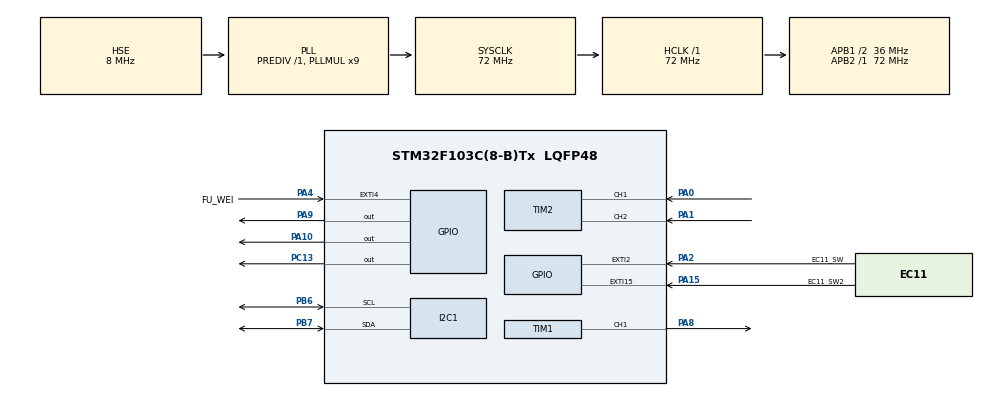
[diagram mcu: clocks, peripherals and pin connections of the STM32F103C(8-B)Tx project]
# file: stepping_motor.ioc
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I2C1.I2C_Mode=I2C_Standard
Mcu.Family=STM32F1
Mcu.Name=STM32F103C(8-B)Tx
Mcu.Package=LQFP48
NVIC.EXTI15_10_IRQn=true\:0\:0\:false\:false\:true\:true\:true\:true
NVIC.EXTI2_IRQn=true\:0\:0\:false\:false\:true\:true\:true\:true
NVIC.EXTI4_IRQn=true\:0\:0\:false\:false\:true\:true\:true\:true
NVIC.PriorityGroup=NVIC_PRIORITYGROUP_4
NVIC.TIM1_BRK_IRQn=true\:0\:0\:false\:false\:true\:true\:true\:true
NVIC.TIM1_CC_IRQn=true\:0\:0\:false\:false\:true\:true\:true\:true
NVIC.TIM1_TRG_COM_IRQn=true\:0\:0\:false\:false\:true\:true\:true\:true
NVIC.TIM1_UP_IRQn=true\:0\:0\:false\:false\:true\:true\:true\:true
NVIC.TIM3_IRQn=true\:0\:0\:false\:false\:true\:true\:true\:true
PA0-WKUP.GPIO_PuPd=GPIO_PULLUP
PA0-WKUP.Signal=S_TIM2_CH1_ETR
PA1.GPIO_PuPd=GPIO_PULLUP
PA1.Signal=S_TIM2_CH2
PA10.Signal=GPIO_Output
PA13.Mode=Serial_Wire
PA13.Signal=SYS_JTMS-SWDIO
PA14.Mode=Serial_Wire
PA14.Signal=SYS_JTCK-SWCLK
PA15.GPIO_Label=EC11_SW2
PA15.GPIO_ModeDefaultEXTI=GPIO_MODE_IT_FALLING
PA15.GPIO_PuPd=GPIO_PULLUP
PA15.Signal=GPXTI15
PA2.GPIO_Label=EC11_SW
PA2.GPIO_ModeDefaultEXTI=GPIO_MODE_IT_FALLING
PA2.GPIO_PuPd=GPIO_PULLUP
PA2.Signal=GPXTI2
PA4.GPIO_Label=FU_WEI
PA4.GPIO_ModeDefaultEXTI=GPIO_MODE_IT_FALLING
PA4.GPIO_PuPd=GPIO_PULLUP
PA4.Signal=GPXTI4
PA8.Signal=S_TIM1_CH1
PA9.Signal=GPIO_Output
PB6.Mode=I2C
PB6.Signal=I2C1_SCL
PB7.Mode=I2C
PB7.Signal=I2C1_SDA
PC13-TAMPER-RTC.PinState=GPIO_PIN_SET
PC13-TAMPER-RTC.Signal=GPIO_Output
PD0-OSC_IN.Mode=HSE-External-Oscillator
PD0-OSC_IN.Signal=RCC_OSC_IN
PD1-OSC_OUT.Mode=HSE-External-Oscillator
PD1-OSC_OUT.Signal=RCC_OSC_OUT
ProjectManager.HeapSize=0x200
ProjectManager.StackSize=0x400
ProjectManager.TargetToolchain=MDK-ARM V5.32
RCC.AHBFreq_Value=72000000
RCC.APB1CLKDivider=RCC_HCLK_DIV2
RCC.APB1Freq_Value=36000000
RCC.APB1TimFreq_Value=72000000
RCC.APB2Freq_Value=72000000
RCC.APB2TimFreq_Value=72000000
RCC.HCLKFreq_Value=72000000
RCC.PLLMUL=RCC_PLL_MUL9
RCC.PLLSourceVirtual=RCC_PLLSOURCE_HSE
RCC.SYSCLKFreq_VALUE=72000000
RCC.SYSCLKSource=RCC_SYSCLKSOURCE_PLLCLK
RCC.USBFreq_Value=72000000
SH.S_TIM1_CH1.0=TIM1_CH1,PWM Generation1 CH1
SH.S_TIM2_CH1_ETR.0=TIM2_CH1,Encoder_Interface
SH.S_TIM2_CH2.0=TIM2_CH2,Encoder_Interface
TIM1.Channel-PWM\ Generation1\ CH1=TIM_CHANNEL_1
TIM1.Period=999
TIM1.Prescaler=71
TIM1.Pulse-PWM\ Generation1\ CH1=500
TIM2.EncoderMode=TIM_ENCODERMODE_TI12
TIM2.IC1Filter=12
TIM2.IC2Filter=12
TIM3.Period=1000-1
TIM3.Prescaler=72-1
VP_TIM1_VS_ClockSourceINT.Mode=Internal
VP_TIM3_VS_ClockSourceINT.Mode=Internal
board=custom

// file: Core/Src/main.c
/* USER CODE BEGIN Header */
/**
  ******************************************************************************
  * @file           : main.c
  * @brief          : Main program body
  ******************************************************************************
  * @attention
  *
  * Copyright (c) 2026 STMicroelectronics.
  * All rights reserved.
  *
  * This software is licensed under terms that can be found in the LICENSE file
  * in the root directory of this software component.
  * If no LICENSE file comes with this software, it is provided AS-IS.
  *
  ******************************************************************************
  */
/* USER CODE END Header */
#include "main.h"
#include "i2c.h"
#include "tim.h"
#include "gpio.h"

/* USER CODE BEGIN Includes */
#include "headfile.h"
/* USER CODE END Includes */

void SystemClock_Config(void);

int main(void)
{

  /* MCU Configuration--------------------------------------------------------*/

  /* Reset of all peripherals, Initializes the Flash interface and the Systick. */
  HAL_Init();

  /* Configure the system clock */
  SystemClock_Config();

  /* USER CODE BEGIN SysInit */
HAL_Delay(1500);
  /* USER CODE END SysInit */

  /* Initialize all configured peripherals */
  MX_GPIO_Init();
  MX_I2C1_Init();
  MX_TIM1_Init();
  MX_TIM2_Init();
  MX_TIM3_Init();
  /* USER CODE BEGIN 2 */
//	HAL_Delay(500);
	OLED_Init();
  //OLED_Fill(0xFF);
  //HAL_Delay(2000);
  OLED_Fill(0x00);

	//OLED_ShowString(30, 2, "HELLO");

	HAL_TIM_Encoder_Start(&htim2, TIM_CHANNEL_ALL);
	//__HAL_TIM_SET_COUNTER(&htim2, 0);
	Load_Parameters();

	__HAL_TIM_SET_COUNTER(&htim2,0);

  HAL_GPIO_WritePin(GPIOA, GPIO_PIN_9, GPIO_PIN_SET);

  //HAL_TIM_PWM_Start(&htim1, TIM_CHANNEL_1);

  //__HAL_TIM_SET_AUTORELOAD(&htim1, 1250-1);//ARR

  //__HAL_TIM_SET_COMPARE(&htim1, TIM_CHANNEL_1, 625);//zhankongbi

	//dianji_kongzhi(up,90,800);
//	HAL_Delay(5000);
//	HAL_TIM_PWM_Stop(&htim1, TIM_CHANNEL_1);
  /* USER CODE END 2 */

  /* Infinite loop */
  /* USER CODE BEGIN WHILE */
  while (1)
  {
		main_pro();
//		HAL_GPIO_WritePin(GPIOC,GPIO_PIN_13,GPIO_PIN_RESET);
//		HAL_Delay(1000);
//		HAL_GPIO_WritePin(GPIOC,GPIO_PIN_13,GPIO_PIN_SET);
//		HAL_Delay(1000);
    /* USER CODE END WHILE */

  }
}

void SystemClock_Config(void)
{
  RCC_OscInitTypeDef RCC_OscInitStruct = {0};
  RCC_ClkInitTypeDef RCC_ClkInitStruct = {0};

  /** Initializes the RCC Oscillators according to the specified parameters
  * in the RCC_OscInitTypeDef structure.
  */
  RCC_OscInitStruct.OscillatorType = RCC_OSCILLATORTYPE_HSE;
  RCC_OscInitStruct.HSEState = RCC_HSE_ON;
  RCC_OscInitStruct.HSEPredivValue = RCC_HSE_PREDIV_DIV1;
  RCC_OscInitStruct.HSIState = RCC_HSI_ON;
  RCC_OscInitStruct.PLL.PLLState = RCC_PLL_ON;
  RCC_OscInitStruct.PLL.PLLSource = RCC_PLLSOURCE_HSE;
  RCC_OscInitStruct.PLL.PLLMUL = RCC_PLL_MUL9;
  if (HAL_RCC_OscConfig(&RCC_OscInitStruct) != HAL_OK)
  {
    Error_Handler();
  }

  /** Initializes the CPU, AHB and APB buses clocks
  */
  RCC_ClkInitStruct.ClockType = RCC_CLOCKTYPE_HCLK|RCC_CLOCKTYPE_SYSCLK
                              |RCC_CLOCKTYPE_PCLK1|RCC_CLOCKTYPE_PCLK2;
  RCC_ClkInitStruct.SYSCLKSource = RCC_SYSCLKSOURCE_PLLCLK;
  RCC_ClkInitStruct.AHBCLKDivider = RCC_SYSCLK_DIV1;
  RCC_ClkInitStruct.APB1CLKDivider = RCC_HCLK_DIV2;
  RCC_ClkInitStruct.APB2CLKDivider = RCC_HCLK_DIV1;

  if (HAL_RCC_ClockConfig(&RCC_ClkInitStruct, FLASH_LATENCY_2) != HAL_OK)
  {
    Error_Handler();
  }
}

void Error_Handler(void)
{
  __disable_irq();
  while (1)
  {
  }
}
